AUTOSAR XML (schema 00046)
package /ComponentTypes
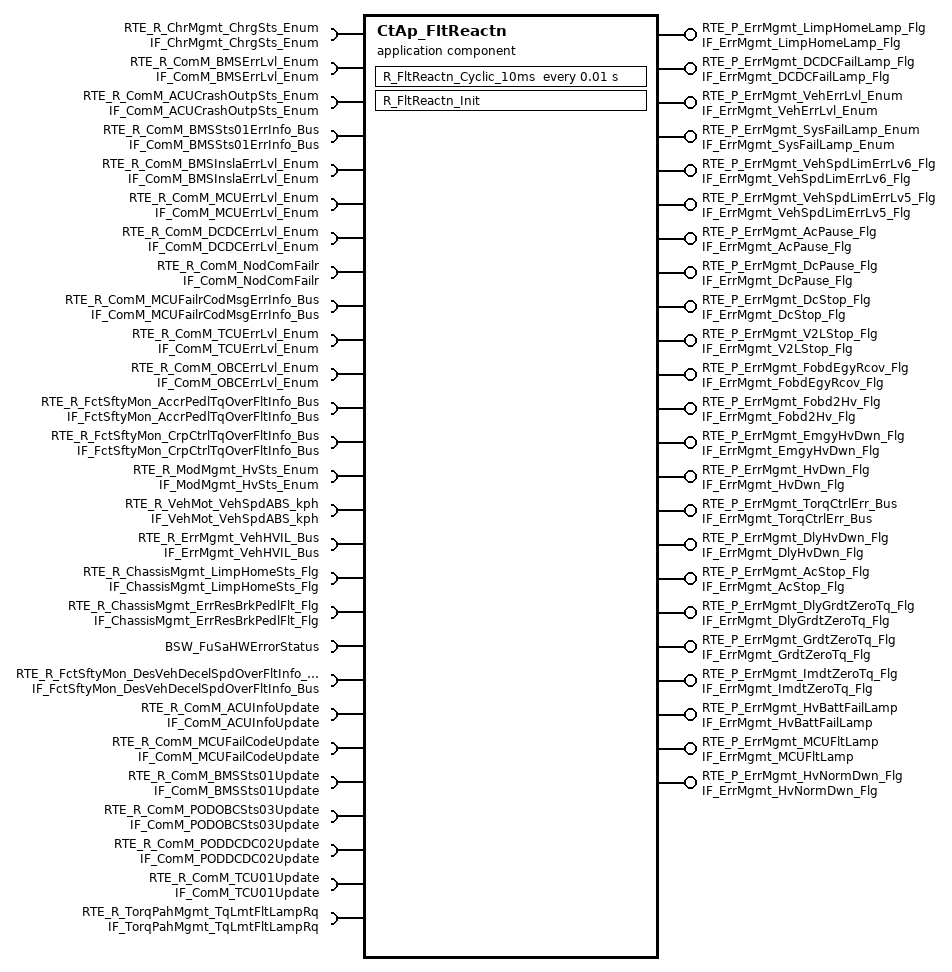
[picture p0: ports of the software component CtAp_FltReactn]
  application sw component type CtAp_FltReactn
    16 x provide port:
      RTE_P_ErrMgmt_LimpHomeLamp_Flg: nonqueued-sender-com-spec{data-element=tec_ErrMgmt_LimpHomeLamp_Flg, init-value=0}, provided-interface=IF_ErrMgmt_LimpHomeLamp_Flg
      RTE_P_ErrMgmt_DCDCFailLamp_Flg: nonqueued-sender-com-spec{data-element=tec_ErrMgmt_DCDCFailLamp_Flg, init-value=0}, provided-interface=IF_ErrMgmt_DCDCFailLamp_Flg
      RTE_P_ErrMgmt_VehErrLvl_Enum: nonqueued-sender-com-spec{data-element=tec_ErrMgmt_VehErrLvl_Enum, init-value=0}, provided-interface=IF_ErrMgmt_VehErrLvl_Enum
      RTE_P_ErrMgmt_SysFailLamp_Enum: nonqueued-sender-com-spec{data-element=tec_ErrMgmt_SysFailLamp_Enum, init-value=0}, provided-interface=IF_ErrMgmt_SysFailLamp_Enum
      RTE_P_ErrMgmt_VehSpdLimErrLv6_Flg: nonqueued-sender-com-spec{data-element=tec_ErrMgmt_VehSpdLimErrLv6_Flg, init-value=0}, provided-interface=IF_ErrMgmt_VehSpdLimErrLv6_Flg
      RTE_P_ErrMgmt_VehSpdLimErrLv5_Flg: nonqueued-sender-com-spec{data-element=tec_ErrMgmt_VehSpdLimErrLv5_Flg, init-value=0}, provided-interface=IF_ErrMgmt_VehSpdLimErrLv5_Flg
      RTE_P_ErrMgmt_AcPause_Flg: nonqueued-sender-com-spec{data-element=tec_ErrMgmt_AcPause_Flg, init-value=0}, provided-interface=IF_ErrMgmt_AcPause_Flg
      RTE_P_ErrMgmt_DcPause_Flg: nonqueued-sender-com-spec{data-element=tec_ErrMgmt_DcPause_Flg, init-value=0}, provided-interface=IF_ErrMgmt_DcPause_Flg
      RTE_P_ErrMgmt_DcStop_Flg: nonqueued-sender-com-spec{data-element=tec_ErrMgmt_DcStop_Flg, init-value=0}, provided-interface=IF_ErrMgmt_DcStop_Flg
      RTE_P_ErrMgmt_V2LStop_Flg: nonqueued-sender-com-spec{data-element=tec_ErrMgmt_V2LStop_Flg, init-value=0}, provided-interface=IF_ErrMgmt_V2LStop_Flg
      RTE_P_ErrMgmt_FobdEgyRcov_Flg: nonqueued-sender-com-spec{data-element=tec_ErrMgmt_FobdEgyRcov_Flg, init-value=0}, provided-interface=IF_ErrMgmt_FobdEgyRcov_Flg
      RTE_P_ErrMgmt_Fobd2Hv_Flg: nonqueued-sender-com-spec{data-element=tec_ErrMgmt_Fobd2Hv_Flg, init-value=0}, provided-interface=IF_ErrMgmt_Fobd2Hv_Flg
      RTE_P_ErrMgmt_EmgyHvDwn_Flg: nonqueued-sender-com-spec{data-element=tec_ErrMgmt_EmgyHvDwn_Flg, init-value=0}, provided-interface=IF_ErrMgmt_EmgyHvDwn_Flg
      RTE_P_ErrMgmt_HvDwn_Flg: nonqueued-sender-com-spec{data-element=tec_ErrMgmt_HvDwn_Flg, init-value=0}, provided-interface=IF_ErrMgmt_HvDwn_Flg
      RTE_P_ErrMgmt_TorqCtrlErr_Bus: nonqueued-sender-com-spec{data-element=tec_ErrMgmt_TorqCtrlErr_Bus, init-value=fields=[ErrMgmt_DlyGrdtZeroTq_Flg:0, ErrMgmt_GrdtZeroTq_Flg:0, ErrMgmt_ImdtZeroTq_Flg:0, ErrMgmt_VehSpdLim_kph:0, ErrMgmt_VehSpdLimEna_Flg:0]}, provided-interface=IF_ErrMgmt_TorqCtrlErr_Bus
      RTE_P_ErrMgmt_DlyHvDwn_Flg: nonqueued-sender-com-spec{data-element=tec_ErrMgmt_DlyHvDwn_Flg, init-value=0}, provided-interface=IF_ErrMgmt_DlyHvDwn_Flg
    11 x require port:
      RTE_R_ChrMgmt_ChrgSts_Enum: nonqueued-receiver-com-spec{data-element=tec_ChrMgmt_ChrgSts_Enum, filter=data-filter-type=ALWAYS, init-value=0}, required-interface=IF_ChrMgmt_ChrgSts_Enum
      RTE_R_ComM_BMSErrLvl_Enum: nonqueued-receiver-com-spec{data-element=tec_ComM_BMSErrLvl_Enum, filter=data-filter-type=ALWAYS, init-value=0}, required-interface=IF_ComM_BMSErrLvl_Enum
      RTE_R_ComM_ACUCrashOutpSts_Enum: nonqueued-receiver-com-spec{data-element=tec_ComM_ACUCrashOutpSts_Enum, filter=data-filter-type=ALWAYS, init-value=0}, required-interface=IF_ComM_ACUCrashOutpSts_Enum
      RTE_R_ComM_BMSSts01ErrInfo_Bus: required-interface=IF_ComM_BMSSts01ErrInfo_Bus
        required-com-specs:
          data-element=tec_ComM_BMSSts01TimeoutInfo_Bus, filter=data-filter-type=ALWAYS, init-value=fields=[ComM_MonStatBMSSts01TimeoutInfo:0, ComM_MonResBMSSts01TimeoutInfo:0, ComM_ErrStatBMSSts01TimeoutInfo:0, ComM_ErrResBMSSts01TimeoutInfo:0]
          data-element=tec_ComM_BMSSts01CRCDTCInfo_Bus, filter=data-filter-type=ALWAYS, init-value=fields=[ComM_MonStatBMSSts01CRCDTCErrorInfo:0, ComM_MonResBMSSts01CRCDTCErrorInfo:0, ComM_ErrStatBMSSts01CRCDTCErrorInfo:0, ComM_ErrResBMSSts01CRCDTCErrorInfo:0]
          data-element=tec_ComM_BMSSts01CRCInfo_Bus, filter=data-filter-type=ALWAYS, init-value=fields=[ComM_MonStatBMSSts01CRCErrorInfo:0, ComM_MonResBMSSts01CRCErrorInfo:0, ComM_ErrStatBMSSts01CRCErrorInfo:0, ComM_ErrResBMSSts01CRCErrorInfo:0]
          data-element=tec_ComM_BMSSts01TimeoutDTCInfo_Bus, filter=data-filter-type=ALWAYS, init-value=fields=[ComM_MonStatBMSSts01TimeoutDTCErrorInfo:0, ComM_MonResBMSSts01TimeoutDTCErrorInfo:0, ComM_ErrStatBMSSts01TimeoutDTCErrorInfo:0, ComM_ErrResBMSSts01TimeoutDTCErrorInfo:0]
          data-element=tec_ComM_BMSSts01E2ETimeoutInfo_Bus, filter=data-filter-type=ALWAYS, init-value=fields=[ComM_MonStatBMSSts01E2ETimeoutInfo:0, ComM_MonResBMSSts01E2ETimeoutInfo:0, ComM_ErrStatBMSSts01E2ETimeoutInfo:0, ComM_ErrResBMSSts01E2ETimeoutInfo:0]
      RTE_R_ComM_BMSInslaErrLvl_Enum: nonqueued-receiver-com-spec{data-element=tec_ComM_BMSInslaErrLvl_Enum, filter=data-filter-type=ALWAYS, init-value=0}, required-interface=IF_ComM_BMSInslaErrLvl_Enum
      RTE_R_ComM_MCUErrLvl_Enum: nonqueued-receiver-com-spec{data-element=tec_ComM_MCUErrLvl_Enum, filter=data-filter-type=ALWAYS, init-value=0}, required-interface=IF_ComM_MCUErrLvl_Enum
      RTE_R_ComM_DCDCErrLvl_Enum: nonqueued-receiver-com-spec{data-element=tec_ComM_DCDCErrLvl_Enum, filter=data-filter-type=ALWAYS, init-value=0}, required-interface=IF_ComM_DCDCErrLvl_Enum
      RTE_R_ComM_NodComFailr: required-interface=IF_ComM_NodComFailr
        required-com-specs:
          data-element=tec_ComM_SGWNodComFailr_Flg, filter=data-filter-type=ALWAYS, init-value=0
          data-element=tec_ComM_CGWNodComFailr_Flg, filter=data-filter-type=ALWAYS, init-value=0
          data-element=tec_ComM_TCUNodComFailr_Flg, filter=data-filter-type=ALWAYS, init-value=0
          data-element=tec_ComM_BCMNodComFailr_Flg, filter=data-filter-type=ALWAYS, init-value=0
          data-element=tec_ComM_PRNDNodComFailr_Flg, filter=data-filter-type=ALWAYS, init-value=0
          data-element=tec_ComM_IVINodComFailr_Flg, filter=data-filter-type=ALWAYS, init-value=0
          data-element=tec_ComM_DCDCNodComFailr_Flg, filter=data-filter-type=ALWAYS, init-value=0
          data-element=tec_ComM_OBCNodComFailr_Flg, filter=data-filter-type=ALWAYS, init-value=0
          data-element=tec_ComM_CHIBSNodComFailr_Flg, filter=data-filter-type=ALWAYS, init-value=0
          data-element=tec_ComM_MCUNodComFailr_Flg, filter=data-filter-type=ALWAYS, init-value=0
          data-element=tec_ComM_EVCOMNodComFailr_Flg, filter=data-filter-type=ALWAYS, init-value=0
          data-element=tec_ComM_EPTIBSNodComFailr_Flg, filter=data-filter-type=ALWAYS, init-value=0
          data-element=tec_ComM_DCMNodComFailr_Flg, filter=data-filter-type=ALWAYS, init-value=0
          data-element=tec_ComM_BMSNodComFailr_Flg, filter=data-filter-type=ALWAYS, init-value=0
          data-element=tec_ComM_ACUNodComFailr_Flg, filter=data-filter-type=ALWAYS, init-value=0
          data-element=tec_ComM_APTCNodComFailr_Flg, filter=data-filter-type=ALWAYS, init-value=0
          data-element=tec_ComM_ADCUNodComFailr_Flg, filter=data-filter-type=ALWAYS, init-value=0
          data-element=tec_ComM_DCMRRNodComFailr_Flg, filter=data-filter-type=ALWAYS, init-value=0
          data-element=tec_ComM_DCMRLNodComFailr_Flg, filter=data-filter-type=ALWAYS, init-value=0
          data-element=tec_ComM_DCMFRNodComFailr_Flg, filter=data-filter-type=ALWAYS, init-value=0
          data-element=tec_ComM_DCMFLNodComFailr_Flg, filter=data-filter-type=ALWAYS, init-value=0
          data-element=tec_ComM_SGWCHNodComFailr_Flg, filter=data-filter-type=ALWAYS, init-value=0
      RTE_R_ComM_MCUFailrCodMsgErrInfo_Bus: required-interface=IF_ComM_MCUFailrCodMsgErrInfo_Bus
        required-com-specs:
          data-element=tec_ComM_MCUFailrCodCRCInfo_Bus, filter=data-filter-type=ALWAYS, init-value=fields=[ComM_MonStatMCUFailrCodCRCErrorInfo:0, ComM_MonResMCUFailrCodCRCErrorInfo:0, ComM_ErrStatMCUFailrCodCRCErrorInfo:0, ComM_ErrResMCUFailrCodCRCErrorInfo:0]
          data-element=tec_ComM_MCUFailrCodE2ETimeoutInfo_Bus, filter=data-filter-type=ALWAYS, init-value=fields=[ComM_MonStatMCUFailrCodE2ETimeouInfo:0, ComM_MonResMCUFailrCodE2ETimeoutInfo:0, ComM_ErrStatMCUFailrCodE2ETimeoutInfo:0, ComM_ErrResMCUFailrCodE2ETimeoutInfo:0]
          data-element=tec_ComM_MCUFailrCodCRCDTCInfo_Bus, filter=data-filter-type=ALWAYS, init-value=fields=[ComM_MonStatMCUFailrCodCRCDTCErrorInfo:0, ComM_MonResMCUFailrCodCRCDTCErrorInfo:0, ComM_ErrStatMCUFailrCodCRCDTCErrorInfo:0, ComM_ErrResMCUFailrCodCRCDTCErrorInfo:0]
          data-element=tec_ComM_MCUFailrCodTimeoutDTCInfo_Bus, filter=data-filter-type=ALWAYS, init-value=fields=[ComM_MonStatMCUFailrCodTimeoutDTCErrorInfo:0, ComM_MonResMCUFailrCodTimeoutDTCErrorInfo:0, ComM_ErrStatMCUFailrCodTimeoutDTCErrorInfo:0, ComM_ErrResMCUFailrCodTimeoutDTCErrorInfo:0]
      RTE_R_ComM_TCUErrLvl_Enum: nonqueued-receiver-com-spec{data-element=tec_ComM_TCUErrLvl_Enum, filter=data-filter-type=ALWAYS, init-value=0}, required-interface=IF_ComM_TCUErrLvl_Enum
      RTE_R_ComM_OBCErrLvl_Enum: nonqueued-receiver-com-spec{data-element=tec_ComM_OBCErrLvl_Enum, filter=data-filter-type=ALWAYS, init-value=0}, required-interface=IF_ComM_OBCErrLvl_Enum
    provide port RTE_P_ErrMgmt_AcStop_Flg: nonqueued-sender-com-spec{data-element=tec_ErrMgmt_AcStop_Flg, init-value=0}, provided-interface=IF_ErrMgmt_AcStop_Flg
    7 x require port:
      RTE_R_FctSftyMon_AccrPedlTqOverFltInfo_Bus: nonqueued-receiver-com-spec{data-element=tec_FctSftyMon_AccrPedlTqOverFltInfo_Bus, filter=data-filter-type=ALWAYS, init-value=fields=[FctSftyMon_MonStatAccrPedlTqOverFltInfo:0, FctSftyMon_MonResAccrPedlTqOverFltInfo:0, FctSftyMon_ErrStatAccrPedlTqOverFltInfo:0, FctSftyMon_ErrResAccrPedlTqOverFltInfo:0]}, required-interface=IF_FctSftyMon_AccrPedlTqOverFltInfo_Bus
      RTE_R_FctSftyMon_CrpCtrlTqOverFltInfo_Bus: nonqueued-receiver-com-spec{data-element=tec_FctSftyMon_CrpCtrlTqOverFltInfo_Bus, filter=data-filter-type=ALWAYS, init-value=fields=[FctSftyMon_MonStatCrpCtrlTqOverFltInfo:0, FctSftyMon_MonResCrpCtrlTqOverFltInfo:0, FctSftyMon_ErrStatCrpCtrlTqOverFltInfo:0, FctSftyMon_ErrResCrpCtrlTqOverFltInfo:0]}, required-interface=IF_FctSftyMon_CrpCtrlTqOverFltInfo_Bus
      RTE_R_ModMgmt_HvSts_Enum: nonqueued-receiver-com-spec{data-element=tec_ModMgmt_HvSts_Enum, filter=data-filter-type=ALWAYS, init-value=0}, required-interface=IF_ModMgmt_HvSts_Enum
      RTE_R_VehMot_VehSpdABS_kph: nonqueued-receiver-com-spec{data-element=tec_VehMot_VehSpdABS_kph, filter=data-filter-type=ALWAYS, init-value=0}, required-interface=IF_VehMot_VehSpdABS_kph
      RTE_R_ErrMgmt_VehHVIL_Bus: nonqueued-receiver-com-spec{data-element=tec_ErrMgmt_VehHVIL_Bus, filter=data-filter-type=ALWAYS, init-value=fields=[ErrMgmt_MonStatVehHVIL:0, ErrMgmt_MonResVehHVIL:0, ErrMgmt_ErrStatVehHVIL:0, ErrMgmt_ErrResVehHVIL:0]}, required-interface=IF_ErrMgmt_VehHVIL_Bus
      RTE_R_ChassisMgmt_LimpHomeSts_Flg: nonqueued-receiver-com-spec{data-element=tec_ChassisMgmt_LimpHomeSts_Flg, filter=data-filter-type=ALWAYS, init-value=0}, required-interface=IF_ChassisMgmt_LimpHomeSts_Flg
      RTE_R_ChassisMgmt_ErrResBrkPedlFlt_Flg: nonqueued-receiver-com-spec{data-element=tec_ChassisMgmt_ErrResBrkPedlFlt_Flg, filter=data-filter-type=ALWAYS, init-value=0}, required-interface=IF_ChassisMgmt_ErrResBrkPedlFlt_Flg
    provide port RTE_P_ErrMgmt_DlyGrdtZeroTq_Flg: nonqueued-sender-com-spec{data-element=tec_ErrMgmt_DlyGrdtZeroTq_Flg, init-value=0}, provided-interface=IF_ErrMgmt_DlyGrdtZeroTq_Flg
    provide port RTE_P_ErrMgmt_GrdtZeroTq_Flg: nonqueued-sender-com-spec{data-element=tec_ErrMgmt_GrdtZeroTq_Flg, init-value=0}, provided-interface=IF_ErrMgmt_GrdtZeroTq_Flg
    provide port RTE_P_ErrMgmt_ImdtZeroTq_Flg: nonqueued-sender-com-spec{data-element=tec_ErrMgmt_ImdtZeroTq_Flg, init-value=0}, provided-interface=IF_ErrMgmt_ImdtZeroTq_Flg
    require port BSW_FuSaHWErrorStatus: nonqueued-receiver-com-spec{data-element=HWErrorStatus, filter=data-filter-type=ALWAYS, init-value=0}, required-interface=BSW_FuSaHWErrorStatus
    provide port RTE_P_ErrMgmt_HvBattFailLamp: nonqueued-sender-com-spec{data-element=tec_ErrMgmt_HvBattFailLamp, init-value=0}, provided-interface=IF_ErrMgmt_HvBattFailLamp
    provide port RTE_P_ErrMgmt_MCUFltLamp: nonqueued-sender-com-spec{data-element=tec_ErrMgmt_MCUFltLamp, init-value=0}, provided-interface=IF_ErrMgmt_MCUFltLamp
    provide port RTE_P_ErrMgmt_HvNormDwn_Flg: nonqueued-sender-com-spec{data-element=tec_ErrMgmt_HvNormDwn_Flg, init-value=0}, provided-interface=IF_ErrMgmt_HvNormDwn_Flg
    8 x require port:
      RTE_R_FctSftyMon_DesVehDecelSpdOverFltInfo_Bus: nonqueued-receiver-com-spec{data-element=tec_FctSftyMon_DesVehDecelSpdOverFltInfo_Bus, filter=data-filter-type=ALWAYS, init-value=fields=[FctSftyMon_MonStatDesVehDecelSpdOverFltInfo:0, FctSftyMon_MonResDesVehDecelSpdOverFltInfo:0, FctSftyMon_ErrStatDesVehDecelSpdOverFltInfo:0, FctSftyMon_ErrResDesVehDecelSpdOverFltInfo:0]}, required-interface=IF_FctSftyMon_DesVehDecelSpdOverFltInfo_Bus
      RTE_R_ComM_ACUInfoUpdate: nonqueued-receiver-com-spec{data-element=tec_ComM_ACUInfoUpdate, filter=data-filter-type=ALWAYS, init-value=0}, required-interface=IF_ComM_ACUInfoUpdate
      RTE_R_ComM_MCUFailCodeUpdate: nonqueued-receiver-com-spec{data-element=tec_ComM_MCUFailCodeUpdate, filter=data-filter-type=ALWAYS, init-value=0}, required-interface=IF_ComM_MCUFailCodeUpdate
      RTE_R_ComM_BMSSts01Update: nonqueued-receiver-com-spec{data-element=tec_ComM_BMSSts01Update, filter=data-filter-type=ALWAYS, init-value=0}, required-interface=IF_ComM_BMSSts01Update
      RTE_R_ComM_PODOBCSts03Update: nonqueued-receiver-com-spec{data-element=tec_ComM_PODOBCSts03Update, filter=data-filter-type=ALWAYS, init-value=0}, required-interface=IF_ComM_PODOBCSts03Update
      RTE_R_ComM_PODDCDC02Update: nonqueued-receiver-com-spec{data-element=tec_ComM_PODDCDC02Update, filter=data-filter-type=ALWAYS, init-value=0}, required-interface=IF_ComM_PODDCDC02Update
      RTE_R_ComM_TCU01Update: nonqueued-receiver-com-spec{data-element=tec_ComM_TCU01Update, filter=data-filter-type=ALWAYS, init-value=0}, required-interface=IF_ComM_TCU01Update
      RTE_R_TorqPahMgmt_TqLmtFltLampRq: nonqueued-receiver-com-spec{data-element=tec_TorqPahMgmt_TqLmtFltLampRq, filter=data-filter-type=ALWAYS, init-value=0}, required-interface=IF_TorqPahMgmt_TqLmtFltLampRq
    behavior CtAp_FltReactn_InternalBehavior
      timing event TMT_R_FltReactn_Cyclic_10ms: start-on-event=R_FltReactn_Cyclic_10ms, period=0.01
      init event CtAp_FltReactn_InitEvent: start-on-event=R_FltReactn_Init
      runnable R_FltReactn_Cyclic_10ms
        data-receive-point-by-arguments:
          34 x access:
            REC_RTE_R_ChrMgmt_ChrgSts_Enum_tec_ChrMgmt_ChrgSts_Enum: accessed-variable=RTE_R_ChrMgmt_ChrgSts_Enum.tec_ChrMgmt_ChrgSts_Enum
            REC_RTE_R_ComM_ACUCrashOutpSts_Enum_tec_ComM_ACUCrashOutpSts_Enum: accessed-variable=RTE_R_ComM_ACUCrashOutpSts_Enum.tec_ComM_ACUCrashOutpSts_Enum
            REC_RTE_R_ComM_BMSErrLvl_Enum_tec_ComM_BMSErrLvl_Enum: accessed-variable=RTE_R_ComM_BMSErrLvl_Enum.tec_ComM_BMSErrLvl_Enum
            REC_RTE_R_ComM_BMSInslaErrLvl_Enum_tec_ComM_BMSInslaErrLvl_Enum: accessed-variable=RTE_R_ComM_BMSInslaErrLvl_Enum.tec_ComM_BMSInslaErrLvl_Enum
            REC_RTE_R_ComM_BMSSts01ErrInfo_Bus_tec_ComM_BMSSts01CRCInfo_Bus: accessed-variable=RTE_R_ComM_BMSSts01ErrInfo_Bus.tec_ComM_BMSSts01CRCInfo_Bus
            REC_RTE_R_ComM_BMSSts01ErrInfo_Bus_tec_ComM_BMSSts01E2ETimeoutInfo_Bus: accessed-variable=RTE_R_ComM_BMSSts01ErrInfo_Bus.tec_ComM_BMSSts01E2ETimeoutInfo_Bus
            REC_RTE_R_ComM_DCDCErrLvl_Enum_tec_ComM_DCDCErrLvl_Enum: accessed-variable=RTE_R_ComM_DCDCErrLvl_Enum.tec_ComM_DCDCErrLvl_Enum
            REC_RTE_R_ComM_MCUErrLvl_Enum_tec_ComM_MCUErrLvl_Enum: accessed-variable=RTE_R_ComM_MCUErrLvl_Enum.tec_ComM_MCUErrLvl_Enum
            REC_RTE_R_ComM_MCUFailrCodMsgErrInfo_Bus_tec_ComM_MCUFailrCodCRCInfo_Bus: accessed-variable=RTE_R_ComM_MCUFailrCodMsgErrInfo_Bus.tec_ComM_MCUFailrCodCRCInfo_Bus
            REC_RTE_R_ComM_MCUFailrCodMsgErrInfo_Bus_tec_ComM_MCUFailrCodE2ETimeoutInfo_Bus: accessed-variable=RTE_R_ComM_MCUFailrCodMsgErrInfo_Bus.tec_ComM_MCUFailrCodE2ETimeoutInfo_Bus
            REC_RTE_R_ComM_NodComFailr_tec_ComM_BMSNodComFailr_Flg: accessed-variable=RTE_R_ComM_NodComFailr.tec_ComM_BMSNodComFailr_Flg
            REC_RTE_R_ComM_NodComFailr_tec_ComM_DCDCNodComFailr_Flg: accessed-variable=RTE_R_ComM_NodComFailr.tec_ComM_DCDCNodComFailr_Flg
            REC_RTE_R_ComM_NodComFailr_tec_ComM_MCUNodComFailr_Flg: accessed-variable=RTE_R_ComM_NodComFailr.tec_ComM_MCUNodComFailr_Flg
            REC_RTE_R_ComM_NodComFailr_tec_ComM_OBCNodComFailr_Flg: accessed-variable=RTE_R_ComM_NodComFailr.tec_ComM_OBCNodComFailr_Flg
            REC_RTE_R_ComM_NodComFailr_tec_ComM_TCUNodComFailr_Flg: accessed-variable=RTE_R_ComM_NodComFailr.tec_ComM_TCUNodComFailr_Flg
            REC_RTE_R_ComM_OBCErrLvl_Enum_tec_ComM_OBCErrLvl_Enum: accessed-variable=RTE_R_ComM_OBCErrLvl_Enum.tec_ComM_OBCErrLvl_Enum
            REC_RTE_R_ComM_TCUErrLvl_Enum_tec_ComM_TCUErrLvl_Enum: accessed-variable=RTE_R_ComM_TCUErrLvl_Enum.tec_ComM_TCUErrLvl_Enum
            REC_RTE_R_FctSftyMon_AccrPedlTqOverFltInfo_Bus_tec_FctSftyMon_AccrPedlTqOverFltInfo_Bus: accessed-variable=RTE_R_FctSftyMon_AccrPedlTqOverFltInfo_Bus.tec_FctSftyMon_AccrPedlTqOverFltInfo_Bus
            REC_RTE_R_FctSftyMon_CrpCtrlTqOverFltInfo_Bus_tec_FctSftyMon_CrpCtrlTqOverFltInfo_Bus: accessed-variable=RTE_R_FctSftyMon_CrpCtrlTqOverFltInfo_Bus.tec_FctSftyMon_CrpCtrlTqOverFltInfo_Bus
            REC_RTE_R_ModMgmt_HvSts_Enum_tec_ModMgmt_HvSts_Enum: accessed-variable=RTE_R_ModMgmt_HvSts_Enum.tec_ModMgmt_HvSts_Enum
            REC_RTE_R_ComM_NodComFailr_tec_ComM_ACUNodComFailr_Flg: accessed-variable=RTE_R_ComM_NodComFailr.tec_ComM_ACUNodComFailr_Flg
            REC_RTE_R_ErrMgmt_VehHVIL_Bus_tec_ErrMgmt_VehHVIL_Bus: accessed-variable=RTE_R_ErrMgmt_VehHVIL_Bus.tec_ErrMgmt_VehHVIL_Bus
            REC_RTE_R_VehMot_VehSpdABS_kph_tec_VehMot_VehSpdABS_kph: accessed-variable=RTE_R_VehMot_VehSpdABS_kph.tec_VehMot_VehSpdABS_kph
            REC_RTE_R_ChassisMgmt_ErrResBrkPedlFlt_Flg_tec_ChassisMgmt_ErrResBrkPedlFlt_Flg: accessed-variable=RTE_R_ChassisMgmt_ErrResBrkPedlFlt_Flg.tec_ChassisMgmt_ErrResBrkPedlFlt_Flg
            REC_RTE_R_ChassisMgmt_LimpHomeSts_Flg_tec_ChassisMgmt_LimpHomeSts_Flg: accessed-variable=RTE_R_ChassisMgmt_LimpHomeSts_Flg.tec_ChassisMgmt_LimpHomeSts_Flg
            REC_BSW_FuSaHWErrorStatus_HWErrorStatus: accessed-variable=BSW_FuSaHWErrorStatus.HWErrorStatus
            REC_RTE_R_FctSftyMon_DesVehDecelSpdOverFltInfo_Bus_tec_FctSftyMon_DesVehDecelSpdOverFltInfo_Bus: accessed-variable=RTE_R_FctSftyMon_DesVehDecelSpdOverFltInfo_Bus.tec_FctSftyMon_DesVehDecelSpdOverFltInfo_Bus
            REC_RTE_R_ComM_ACUInfoUpdate_tec_ComM_ACUInfoUpdate: accessed-variable=RTE_R_ComM_ACUInfoUpdate.tec_ComM_ACUInfoUpdate
            REC_RTE_R_ComM_BMSSts01Update_tec_ComM_BMSSts01Update: accessed-variable=RTE_R_ComM_BMSSts01Update.tec_ComM_BMSSts01Update
            REC_RTE_R_ComM_MCUFailCodeUpdate_tec_ComM_MCUFailCodeUpdate: accessed-variable=RTE_R_ComM_MCUFailCodeUpdate.tec_ComM_MCUFailCodeUpdate
            REC_RTE_R_ComM_PODDCDC02Update_tec_ComM_PODDCDC02Update: accessed-variable=RTE_R_ComM_PODDCDC02Update.tec_ComM_PODDCDC02Update
            REC_RTE_R_ComM_PODOBCSts03Update_tec_ComM_PODOBCSts03Update: accessed-variable=RTE_R_ComM_PODOBCSts03Update.tec_ComM_PODOBCSts03Update
            REC_RTE_R_ComM_TCU01Update_tec_ComM_TCU01Update: accessed-variable=RTE_R_ComM_TCU01Update.tec_ComM_TCU01Update
            REC_RTE_R_TorqPahMgmt_TqLmtFltLampRq_tec_TorqPahMgmt_TqLmtFltLampRq: accessed-variable=RTE_R_TorqPahMgmt_TqLmtFltLampRq.tec_TorqPahMgmt_TqLmtFltLampRq
        data-send-points:
          23 x access:
            SEND_RTE_P_ErrMgmt_AcPause_Flg_tec_ErrMgmt_AcPause_Flg: accessed-variable=RTE_P_ErrMgmt_AcPause_Flg.tec_ErrMgmt_AcPause_Flg
            SEND_RTE_P_ErrMgmt_AcStop_Flg_tec_ErrMgmt_AcStop_Flg: accessed-variable=RTE_P_ErrMgmt_AcStop_Flg.tec_ErrMgmt_AcStop_Flg
            SEND_RTE_P_ErrMgmt_DCDCFailLamp_Flg_tec_ErrMgmt_DCDCFailLamp_Flg: accessed-variable=RTE_P_ErrMgmt_DCDCFailLamp_Flg.tec_ErrMgmt_DCDCFailLamp_Flg
            SEND_RTE_P_ErrMgmt_DcPause_Flg_tec_ErrMgmt_DcPause_Flg: accessed-variable=RTE_P_ErrMgmt_DcPause_Flg.tec_ErrMgmt_DcPause_Flg
            SEND_RTE_P_ErrMgmt_DcStop_Flg_tec_ErrMgmt_DcStop_Flg: accessed-variable=RTE_P_ErrMgmt_DcStop_Flg.tec_ErrMgmt_DcStop_Flg
            SEND_RTE_P_ErrMgmt_DlyHvDwn_Flg_tec_ErrMgmt_DlyHvDwn_Flg: accessed-variable=RTE_P_ErrMgmt_DlyHvDwn_Flg.tec_ErrMgmt_DlyHvDwn_Flg
            SEND_RTE_P_ErrMgmt_EmgyHvDwn_Flg_tec_ErrMgmt_EmgyHvDwn_Flg: accessed-variable=RTE_P_ErrMgmt_EmgyHvDwn_Flg.tec_ErrMgmt_EmgyHvDwn_Flg
            SEND_RTE_P_ErrMgmt_Fobd2Hv_Flg_tec_ErrMgmt_Fobd2Hv_Flg: accessed-variable=RTE_P_ErrMgmt_Fobd2Hv_Flg.tec_ErrMgmt_Fobd2Hv_Flg
            SEND_RTE_P_ErrMgmt_FobdEgyRcov_Flg_tec_ErrMgmt_FobdEgyRcov_Flg: accessed-variable=RTE_P_ErrMgmt_FobdEgyRcov_Flg.tec_ErrMgmt_FobdEgyRcov_Flg
            SEND_RTE_P_ErrMgmt_HvDwn_Flg_tec_ErrMgmt_HvDwn_Flg: accessed-variable=RTE_P_ErrMgmt_HvDwn_Flg.tec_ErrMgmt_HvDwn_Flg
            SEND_RTE_P_ErrMgmt_LimpHomeLamp_Flg_tec_ErrMgmt_LimpHomeLamp_Flg: accessed-variable=RTE_P_ErrMgmt_LimpHomeLamp_Flg.tec_ErrMgmt_LimpHomeLamp_Flg
            SEND_RTE_P_ErrMgmt_SysFailLamp_Enum_tec_ErrMgmt_SysFailLamp_Enum: accessed-variable=RTE_P_ErrMgmt_SysFailLamp_Enum.tec_ErrMgmt_SysFailLamp_Enum
            SEND_RTE_P_ErrMgmt_TorqCtrlErr_Bus_tec_ErrMgmt_TorqCtrlErr_Bus: accessed-variable=RTE_P_ErrMgmt_TorqCtrlErr_Bus.tec_ErrMgmt_TorqCtrlErr_Bus
            SEND_RTE_P_ErrMgmt_V2LStop_Flg_tec_ErrMgmt_V2LStop_Flg: accessed-variable=RTE_P_ErrMgmt_V2LStop_Flg.tec_ErrMgmt_V2LStop_Flg
            SEND_RTE_P_ErrMgmt_VehErrLvl_Enum_tec_ErrMgmt_VehErrLvl_Enum: accessed-variable=RTE_P_ErrMgmt_VehErrLvl_Enum.tec_ErrMgmt_VehErrLvl_Enum
            SEND_RTE_P_ErrMgmt_VehSpdLimErrLv5_Flg_tec_ErrMgmt_VehSpdLimErrLv5_Flg: accessed-variable=RTE_P_ErrMgmt_VehSpdLimErrLv5_Flg.tec_ErrMgmt_VehSpdLimErrLv5_Flg
            SEND_RTE_P_ErrMgmt_VehSpdLimErrLv6_Flg_tec_ErrMgmt_VehSpdLimErrLv6_Flg: accessed-variable=RTE_P_ErrMgmt_VehSpdLimErrLv6_Flg.tec_ErrMgmt_VehSpdLimErrLv6_Flg
            SEND_RTE_P_ErrMgmt_DlyGrdtZeroTq_Flg_tec_ErrMgmt_DlyGrdtZeroTq_Flg: accessed-variable=RTE_P_ErrMgmt_DlyGrdtZeroTq_Flg.tec_ErrMgmt_DlyGrdtZeroTq_Flg
            SEND_RTE_P_ErrMgmt_GrdtZeroTq_Flg_tec_ErrMgmt_GrdtZeroTq_Flg: accessed-variable=RTE_P_ErrMgmt_GrdtZeroTq_Flg.tec_ErrMgmt_GrdtZeroTq_Flg
            SEND_RTE_P_ErrMgmt_ImdtZeroTq_Flg_tec_ErrMgmt_ImdtZeroTq_Flg: accessed-variable=RTE_P_ErrMgmt_ImdtZeroTq_Flg.tec_ErrMgmt_ImdtZeroTq_Flg
            SEND_RTE_P_ErrMgmt_HvBattFailLamp_tec_ErrMgmt_HvBattFailLamp: accessed-variable=RTE_P_ErrMgmt_HvBattFailLamp.tec_ErrMgmt_HvBattFailLamp
            SEND_RTE_P_ErrMgmt_MCUFltLamp_tec_ErrMgmt_MCUFltLamp: accessed-variable=RTE_P_ErrMgmt_MCUFltLamp.tec_ErrMgmt_MCUFltLamp
            SEND_RTE_P_ErrMgmt_HvNormDwn_Flg_tec_ErrMgmt_HvNormDwn_Flg: accessed-variable=RTE_P_ErrMgmt_HvNormDwn_Flg.tec_ErrMgmt_HvNormDwn_Flg
      runnable R_FltReactn_Init
  swc implementation CtAp_FltReactn_Implementation: behavior=CtAp_FltReactn_InternalBehavior
